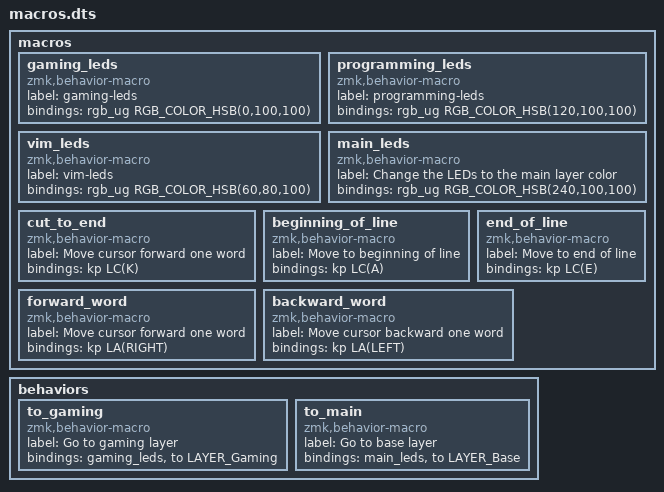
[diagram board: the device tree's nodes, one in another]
    /* Macros for changing the LED colors */
    macros {
        gaming_leds: gaming_leds {
            label = "gaming-leds";
            compatible = "zmk,behavior-macro";
            #binding-cells = <0>;
            bindings = <&rgb_ug RGB_COLOR_HSB(0,100,100)>;
        };
        programming_leds: programming_leds {
            label = "programming-leds";
            compatible = "zmk,behavior-macro";
            #binding-cells = <0>;
            bindings = <&rgb_ug RGB_COLOR_HSB(120,100,100)>;
        };
        vim_leds: vim_leds {
            label = "vim-leds";
            compatible = "zmk,behavior-macro";
            #binding-cells = <0>;
            bindings = <&rgb_ug RGB_COLOR_HSB(60,80,100)>;
        };
        main_leds: main_leds {
            label = "Change the LEDs to the main layer color";
            compatible = "zmk,behavior-macro";
            #binding-cells = <0>;
            bindings = <&rgb_ug RGB_COLOR_HSB(240,100,100)>;
        };
        cut_to_end: cut_to_end {
            label = "Move cursor forward one word";
            compatible = "zmk,behavior-macro";
            #binding-cells = <0>;
            bindings = <&kp LC(K)>;
        };
        beginning_of_line: beginning_of_line {
            label = "Move to beginning of line";
            compatible = "zmk,behavior-macro";
            #binding-cells = <0>;
            bindings = <&kp LC(A)>;
        };
        end_of_line: end_of_line {
            label = "Move to end of line";
            compatible = "zmk,behavior-macro";
            #binding-cells = <0>;
            bindings = <&kp LC(E)>;
        };
        forward_word: forward_word {
            label = "Move cursor forward one word";
            compatible = "zmk,behavior-macro";
            #binding-cells = <0>;
            bindings = <&kp LA(RIGHT)>;
        };
        backward_word: backward_word {
            label = "Move cursor backward one word";
            compatible = "zmk,behavior-macro";
            #binding-cells = <0>;
            bindings = <&kp LA(LEFT)>;
        };
    };

    /* Actions to perform when switching between various layers */
    behaviors {
        to_gaming: to_gaming {
            compatible = "zmk,behavior-macro";
            label = "Go to gaming layer";
            #binding-cells = <0>;

            bindings = <&gaming_leds &to LAYER_Gaming>;
        };
        to_main: to_main {
            compatible = "zmk,behavior-macro";
            label = "Go to base layer";
            #binding-cells = <0>;

            bindings = <&main_leds &to LAYER_Base>;
        };
    };
